# STM32U585 register map
File version: 1.3
CPU: CM33 r0p1, little endian, MPU, FPU, 4 interrupt priority bits
Registers are 32-bit, read-write, reset 0x0 unless marked. A register's access mark holds for its fields unless they carry their own. Offsets are from the block's base; [hi:lo] are bit positions; {n}, {i} and the like mark numbered series.

## TAMP — Tamper and backup registers
Base 0x46007C00
Same registers: SEC_TAMP 0x56007C00
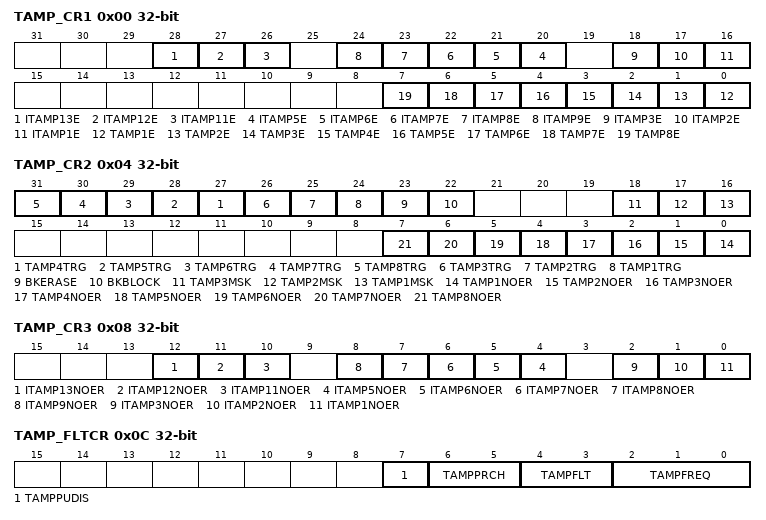
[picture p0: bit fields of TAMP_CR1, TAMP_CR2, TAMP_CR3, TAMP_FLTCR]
0x00 TAMP_CR1 — TAMP control register 1
  [28] ITAMP13E — Internal tamper 13 enable
  [27] ITAMP12E — Internal tamper 12 enable
  [26] ITAMP11E — Internal tamper 11 enable
  [n+15] ITAMP{n}E (n=5..9) — Internal tamper {n} enable
  [18] ITAMP3E — Internal tamper 3 enable
  [17] ITAMP2E — Internal tamper 2 enable
  [16] ITAMP1E — Internal tamper 1 enable
  [n-1] TAMP{n}E (n=1..8) — Tamper detection on TAMP_IN{n} enable
0x04 TAMP_CR2 access per field — TAMP control register 2
  [n+23] TAMP{n}TRG rw (n=4..8) — Active level for tamper {n} input (active mode disabled) If TAMPFLT = 00 Tamper {n} input rising edge and high level triggers a tamper detection event. If TAMPFLT = 00 Tamper {n} input falling edge and low level triggers a tamper detection event.
  [26] TAMP3TRG rw — Active level for tamper 3 input If TAMPFLT = 00 Tamper 3 input rising edge and high level triggers a tamper detection event. If TAMPFLT = 00 Tamper 3 input falling edge and low level triggers a tamper detection event.
  [25] TAMP2TRG rw — Active level for tamper 2 input If TAMPFLT = 00 Tamper 2 input rising edge and high level triggers a tamper detection event. If TAMPFLT = 00 Tamper 2 input falling edge and low level triggers a tamper detection event.
  [24] TAMP1TRG rw — Active level for tamper 1 input If TAMPFLT = 00 Tamper 1 input rising edge and high level triggers a tamper detection event. If TAMPFLT = 00 Tamper 1 input falling edge and low level triggers a tamper detection event.
  [23] BKERASE wo — Backup registers and device secrets erase Writing '1 to this bit reset the backup registers and device secrets(1). Writing 0 has no effect. This bit is always read as 0.
  [22] BKBLOCK rw — Backup registers and device secrets access blocked
  [18] TAMP3MSK rw — Tamper 3 mask The tamper 3 interrupt must not be enabled when TAMP3MSK is set.
  [17] TAMP2MSK rw — Tamper 2 mask The tamper 2 interrupt must not be enabled when TAMP2MSK is set.
  [16] TAMP1MSK rw — Tamper 1 mask The tamper 1 interrupt must not be enabled when TAMP1MSK is set.
  [n-1] TAMP{n}NOER rw (n=1..8) — Tamper {n} no erase
0x08 TAMP_CR3 — TAMP control register 3
  [12] ITAMP13NOER — Internal Tamper 13 no erase
  [11] ITAMP12NOER — Internal Tamper 12 no erase
  [10] ITAMP11NOER — Internal Tamper 11 no erase
  [n-1] ITAMP{n}NOER (n=5..9) — Internal Tamper {n} no erase
  [2] ITAMP3NOER — Internal Tamper 3 no erase
  [1] ITAMP2NOER — Internal Tamper 2 no erase
  [0] ITAMP1NOER — Internal Tamper 1 no erase
0x0C TAMP_FLTCR — TAMP filter control register
  [7] TAMPPUDIS — TAMP_INx pull-up disable This bit determines if each of the TAMPx pins are precharged before each sample.
  [6:5] TAMPPRCH — TAMP_INx precharge duration These bit determines the duration of time during which the pull-up/is activated before each sample. TAMPPRCH is valid for each of the TAMP_INx inputs.
  [4:3] TAMPFLT — TAMP_INx filter count These bits determines the number of consecutive samples at the specified level (TAMP*TRG) needed to activate a tamper event. TAMPFLT is valid for each of the TAMP_INx inputs.
  [2:0] TAMPFREQ — Tamper sampling frequency Determines the frequency at which each of the TAMP_INx inputs are sampled.
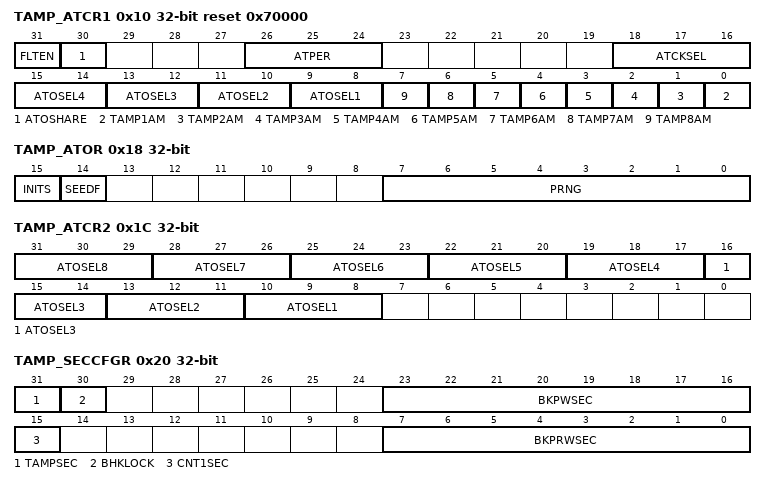
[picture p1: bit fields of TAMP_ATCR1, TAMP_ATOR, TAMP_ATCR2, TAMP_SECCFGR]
0x10 TAMP_ATCR1 reset 0x70000 — TAMP active tamper control register 1
  [31] FLTEN — Active tamper filter enable
  [30] ATOSHARE — Active tamper output sharing TAMP_IN1 is compared with TAMPOUTSEL1 TAMP_IN2 is compared with TAMPOUTSEL2 TAMP_IN3 is compared with TAMPOUTSEL3 TAMP_IN4 is compared with TAMPOUTSEL4 TAMP_IN5 is compared with TAMPOUTSEL5 TAMP_IN6 is compared with TAMPOUTSEL6 TAMP_IN7 is compared with TAMPOUTSEL7 TAMP_IN8 is compared with TAMPOUTSEL8
  [26:24] ATPER — Active tamper output change period The tamper output is changed every CK_ATPER = (2ATPER x CK_ATPRE) cycles. Refer to .
  [18:16] ATCKSEL — Active tamper RTC asynchronous prescaler clock selection These bits selects the RTC asynchronous prescaler stage output.The selected clock is CK_ATPRE. fCK_ATPRE = fRTCCLK / 2ATCKSEL when (PREDIV_A+1) = 128. ... These bits can be written only when all active tampers are disabled. The write protection remains for up to 1.5 ck_atpre cycles after all the active tampers are disable.
  [15:14] ATOSEL4 — Active tamper shared output 4 selection The selected output must be available in the package pinout.
  [13:12] ATOSEL3 — Active tamper shared output 3 selection The selected output must be available in the package pinout
  [11:10] ATOSEL2 — Active tamper shared output 2 selection The selected output must be available in the package pinout
  [9:8] ATOSEL1 — Active tamper shared output 1 selection The selected output must be available in the package pinout
  [n-1] TAMP{n}AM (n=1..8) — Tamper {n} active mode
0x14 TAMP_ATSEEDR wo — TAMP active tamper seed register
  [31:0] SEED — Pseudo-random generator seed value This register must be written four times with 32-bit values to provide the 128-bit seed to the PRNG. Writing to this register automatically sends the seed value to the PRNG.
0x18 TAMP_ATOR ro — TAMP active tamper output register
  [15] INITS — Active tamper initialization status This flag is set by hardware when the PRNG has absorbed the first 128-bit seed, meaning that the enabled active tampers are functional. This flag is cleared when the active tampers are disabled.
  [14] SEEDF — Seed running flag This flag is set by hardware when a new seed is written in the TAMP_ATSEEDR. It is cleared by hardware when the PRNG has absorbed this new seed, and by system reset. The TAMP APB cock must not be switched off as long as SEEDF is set.
  [7:0] PRNG — Pseudo-random generator value This field provides the values of the PRNG output. Because of potential inconsistencies due to synchronization delays, PRNG must be read at least twice. The read value is correct if it is equal to previous read value. This field can only be read when the APB is in secure mode.
0x1C TAMP_ATCR2 — TAMP active tamper control register 2
  [3n+7:3n+5] ATOSEL{n} (n=5..8) — Active tamper shared output {n} selection The selected output must be available in the package pinout.
  [19:17] ATOSEL4 — Active tamper shared output 4 selection The selected output must be available in the package pinout. Bits 18:17 are the mirror of ATOSEL2[1:0] in the TAMP_ATCR1, and so can also be read or written through TAMP_ATCR1.
  [16:14] ATOSEL3 — Active tamper shared output 3 selection The selected output must be available in the package pinout. Bits 15:14 are the mirror of ATOSEL3[1:0] in the TAMP_ATCR1, and so can also be read or written through TAMP_ATCR1.
  [13:11] ATOSEL2 — Active tamper shared output 2 selection The selected output must be available in the package pinout. Bits 12:11 are the mirror of ATOSEL2[1:0] in the TAMP_ATCR1, and so can also be read or written through TAMP_ATCR1.
  [10:8] ATOSEL1 — Active tamper shared output 1 selection The selected output must be available in the package pinout. Bits 9:8 are the mirror of ATOSEL1[1:0] in the TAMP_ATCR1, and so can also be read or written through TAMP_ATCR1.
0x20 TAMP_SECCFGR — TAMP secure mode register
  [31] TAMPSEC — Tamper protection (excluding monotonic counters and backup registers) Note: Refer to for details on the read protection.
  [30] BHKLOCK — Boot hardware key lock This bit can be read and can only be written to 1 by software. It is cleared by hardware together with the backup registers following a tamper detection event or when the readout protection (RDP) is disabled.
  [23:16] BKPWSEC — Backup registers write protection offset Protection zone 2 is defined for backup registers from TAMP_BKPyR (y = BKPRWSEC, from 0 to 128) to TAMP_BKPzR (z = BKPWSEC-1, from 0 to 128, BKPWSEC ¥ BKPRWSEC): if TZEN=1, these backup registers can be written only with secure access. They can be read with secure or non-secure access. Protection zone 3 defined for backup registers from TAMP_BKPtR (t = BKPWSEC, from 0 to 127). They can be read or written with secure or non-secure access. If TZEN=0: the protection zone 2 can be read and written with non-secure access. If BKPWSEC = 0 or if BKPWSEC ¤ BKPRWSEC: there is no protection zone 2. If BKPWPRIV is set, BKPRWSEC[7:0] can be written only in privileged mode.
  [15] CNT1SEC — Monotonic counter 1 secure protection
  [7:0] BKPRWSEC — Backup registers read/write protection offset Protection zone 1 is defined for backup registers from TAMP_BKP0R to TAMP_BKPxR (x = BKPRWSEC-1, from 0 to 128). if TZEN=1, these backup registers can be read and written only with secure access. If TZEN=0: the protection zone 1 can be read and written with non-secure access. If BKPRWSEC = 0: there is no protection zone 1. If BKPRWPRIV is set, BKPRWSEC[7:0] can be written only in privileged mode.
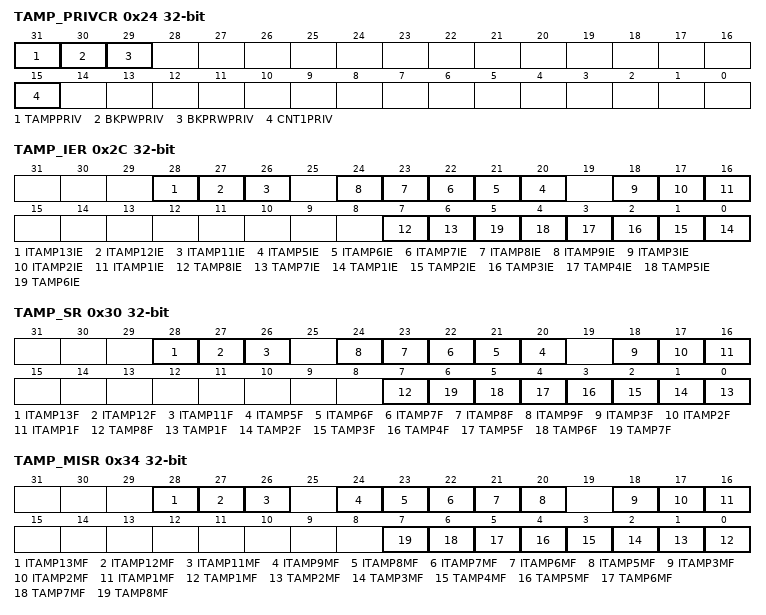
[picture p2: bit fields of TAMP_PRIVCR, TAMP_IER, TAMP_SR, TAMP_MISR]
0x24 TAMP_PRIVCR — TAMP privilege mode control register
  [31] TAMPPRIV — Tamper privilege protection (excluding backup registers) Note: Refer to for details on the read protection.
  [30] BKPWPRIV — Backup registers zone 2 privilege protection
  [29] BKPRWPRIV — Backup registers zone 1 privilege protection
  [15] CNT1PRIV — Monotonic counter 1 privilege protection
0x2C TAMP_IER — TAMP interrupt enable register
  [28] ITAMP13IE — Internal tamper 13 interrupt enable
  [27] ITAMP12IE — Internal tamper 12 interrupt enable
  [26] ITAMP11IE — Internal tamper 11 interrupt enable
  [n+15] ITAMP{n}IE (n=5..9) — Internal tamper {n} interrupt enable
  [18] ITAMP3IE — Internal tamper 3 interrupt enable
  [17] ITAMP2IE — Internal tamper 2 interrupt enable
  [16] ITAMP1IE — Internal tamper 1 interrupt enable
  [7] TAMP8IE — Tamper 8 interrupt enable
  [6] TAMP7IE — Tamper 7interrupt enable
  [n-1] TAMP{n}IE (n=1..6) — Tamper {n} interrupt enable
0x30 TAMP_SR ro — TAMP status register
  [28] ITAMP13F — Internal tamper 13 flag This flag is set by hardware when a tamper detection event is detected on the internal tamper 13.
  [27] ITAMP12F — Internal tamper 12 flag This flag is set by hardware when a tamper detection event is detected on the internal tamper 12.
  [26] ITAMP11F — Internal tamper 11 flag This flag is set by hardware when a tamper detection event is detected on the internal tamper 11.
  [n+15] ITAMP{n}F (n=5..9) — Internal tamper {n} flag This flag is set by hardware when a tamper detection event is detected on the internal tamper {n}.
  [18] ITAMP3F — Internal tamper 3 flag This flag is set by hardware when a tamper detection event is detected on the internal tamper 3.
  [17] ITAMP2F — Internal tamper 2 flag This flag is set by hardware when a tamper detection event is detected on the internal tamper 2.
  [16] ITAMP1F — Internal tamper 1 flag This flag is set by hardware when a tamper detection event is detected on the internal tamper 1.
  [7] TAMP8F — TAMP8 detection flag This flag is set by hardware when a tamper detection event is detected on the TAMP8 input
  [n-1] TAMP{n}F (n=1..7) — TAMP{n} detection flag This flag is set by hardware when a tamper detection event is detected on the TAMP{n} input.
0x34 TAMP_MISR ro — TAMP non-secure masked interrupt status register
  [28] ITAMP13MF — internal tamper 13 non-secure interrupt masked flag This flag is set by hardware when the internal tamper 13 non-secure interrupt is raised.
  [27] ITAMP12MF — internal tamper 12 non-secure interrupt masked flag This flag is set by hardware when the internal tamper 12 non-secure interrupt is raised.
  [26] ITAMP11MF — internal tamper 11 non-secure interrupt masked flag This flag is set by hardware when the internal tamper 11 non-secure interrupt is raised.
  [24] ITAMP9MF — internal tamper 9 non-secure interrupt masked flag This flag is set by hardware when the internal tamper 9 non-secure interrupt is raised.
  [23] ITAMP8MF — Internal tamper 8 non-secure interrupt masked flag This flag is set by hardware when the internal tamper 8 non-secure interrupt is raised.
  [22] ITAMP7MF — VCORE monitoring tamper non-secure interrupt masked flag This flag is set by hardware when the internal tamper 7 non-secure interrupt is raised.
  [21] ITAMP6MF — Internal tamper 6 non-secure interrupt masked flag This flag is set by hardware when the internal tamper 6 non-secure interrupt is raised.
  [20] ITAMP5MF — Internal tamper 5 non-secure interrupt masked flag This flag is set by hardware when the internal tamper 5 non-secure interrupt is raised.
  [18] ITAMP3MF — Internal tamper 3 non-secure interrupt masked flag This flag is set by hardware when the internal tamper 3 non-secure interrupt is raised.
  [17] ITAMP2MF — Internal tamper 2 non-secure interrupt masked flag This flag is set by hardware when the internal tamper 2 non-secure interrupt is raised.
  [16] ITAMP1MF — Internal tamper 1 non-secure interrupt masked flag This flag is set by hardware when the internal tamper 1 non-secure interrupt is raised.
  [n-1] TAMP{n}MF (n=1..8) — TAMP{n} non-secure interrupt masked flag This flag is set by hardware when the tamper {n} non-secure interrupt is raised.
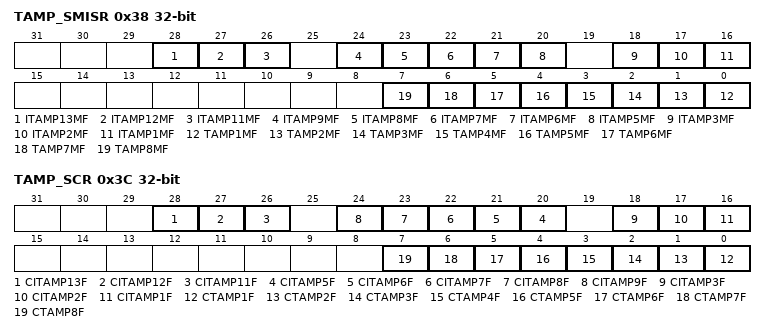
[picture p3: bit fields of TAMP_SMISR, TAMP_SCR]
0x38 TAMP_SMISR ro — TAMP secure masked interrupt status register
  [28] ITAMP13MF — internal tamper 13 secure interrupt masked flag This flag is set by hardware when the internal tamper 13 secure interrupt is raised.
  [27] ITAMP12MF — internal tamper 12 secure interrupt masked flag This flag is set by hardware when the internal tamper 12 secure interrupt is raised.
  [26] ITAMP11MF — internal tamper 11 secure interrupt masked flag This flag is set by hardware when the internal tamper 11 secure interrupt is raised.
  [24] ITAMP9MF — internal tamper 9 secure interrupt masked flag This flag is set by hardware when the internal tamper 9 secure interrupt is raised.
  [23] ITAMP8MF — Internal tamper 8 secure interrupt masked flag This flag is set by hardware when the internal tamper 8 secure interrupt is raised.
  [22] ITAMP7MF — VCORE monitoring tamper secure interrupt masked flag This flag is set by hardware when the internal tamper 7 secure interrupt is raised.
  [21] ITAMP6MF — Internal tamper 6 secure interrupt masked flag This flag is set by hardware when the internal tamper 6 secure interrupt is raised.
  [20] ITAMP5MF — Internal tamper 5 secure interrupt masked flag This flag is set by hardware when the internal tamper 5 secure interrupt is raised.
  [18] ITAMP3MF — Internal tamper 3 secure interrupt masked flag This flag is set by hardware when the internal tamper 3 secure interrupt is raised.
  [17] ITAMP2MF — Internal tamper 2 secure interrupt masked flag This flag is set by hardware when the internal tamper 2 secure interrupt is raised.
  [16] ITAMP1MF — Internal tamper 1 secure interrupt masked flag This flag is set by hardware when the internal tamper 1 secure interrupt is raised.
  [n-1] TAMP{n}MF (n=1..8) — TAMP{n} secure interrupt masked flag This flag is set by hardware when the tamper {n} secure interrupt is raised.
0x3C TAMP_SCR wo — TAMP status clear register
  [28] CITAMP13F — Clear ITAMP13 detection flag Writing 1 in this bit clears the ITAMP13F bit in the TAMP_SR register.
  [27] CITAMP12F — Clear ITAMP12 detection flag Writing 1 in this bit clears the ITAMP12F bit in the TAMP_SR register.
  [26] CITAMP11F — Clear ITAMP11 detection flag Writing 1 in this bit clears the ITAMP11F bit in the TAMP_SR register.
  [n+15] CITAMP{n}F (n=5..9) — Clear ITAMP{n} detection flag Writing 1 in this bit clears the ITAMP{n}F bit in the TAMP_SR register.
  [18] CITAMP3F — Clear ITAMP3 detection flag Writing 1 in this bit clears the ITAMP3F bit in the TAMP_SR register.
  [17] CITAMP2F — Clear ITAMP2 detection flag Writing 1 in this bit clears the ITAMP2F bit in the TAMP_SR register.
  [16] CITAMP1F — Clear ITAMP1 detection flag Writing 1 in this bit clears the ITAMP1F bit in the TAMP_SR register.
  [n-1] CTAMP{n}F (n=1..8) — Clear TAMP{n} detection flag Writing 1 in this bit clears the TAMP{n}F bit in the TAMP_SR register.
0x40 TAMP_COUNT1R ro — TAMP monotonic counter 1 register
  [31:0] COUNT — This register is read-only only and is incremented by one when a write access is done to this register. This register cannot roll-over and is frozen when reaching the maximum value.
0x54 TAMP_ERCFGR — TAMP erase configuration register
  [0] ERCFG0 — Configurable device secrets configuration
{0x100+4i} TAMP_BKP{i}R (i=0..31) — TAMP backup {i} register
  [31:0] BKP — The application can write or read data to and from these registers. In the default (ERASE) configuration this register is reset on a tamper detection event. It is forced to reset value as long as there is at least one internal or external tamper flag being set. This register is also reset when the readout protection (RDP) is disabled.
